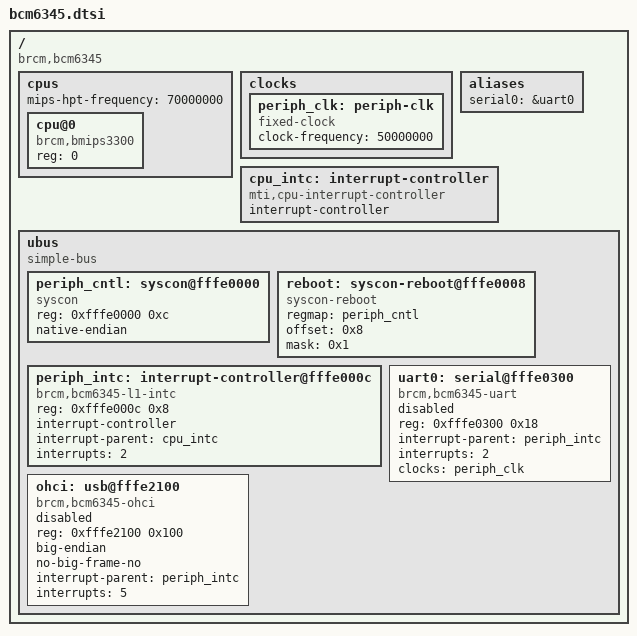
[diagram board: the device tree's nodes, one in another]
/ {
	#address-cells = <1>;
	#size-cells = <1>;
	compatible = "brcm,bcm6345";

	cpus {
		#address-cells = <1>;
		#size-cells = <0>;

		mips-hpt-frequency = <70000000>;

		cpu@0 {
			compatible = "brcm,bmips3300";
			device_type = "cpu";
			reg = <0>;
		};
	};

	clocks {
		periph_clk: periph-clk {
			compatible = "fixed-clock";
			#clock-cells = <0>;
			clock-frequency = <50000000>;
		};
	};

	aliases {
		serial0 = &uart0;
	};

	cpu_intc: interrupt-controller {
		#address-cells = <0>;
		compatible = "mti,cpu-interrupt-controller";

		interrupt-controller;
		#interrupt-cells = <1>;
	};

	ubus {
		#address-cells = <1>;
		#size-cells = <1>;

		compatible = "simple-bus";
		ranges;

		periph_cntl: syscon@fffe0000 {
			compatible = "syscon";
			reg = <0xfffe0000 0xc>;
			native-endian;
		};

		reboot: syscon-reboot@fffe0008 {
			compatible = "syscon-reboot";
			regmap = <&periph_cntl>;
			offset = <0x8>;
			mask = <0x1>;
		};

		periph_intc: interrupt-controller@fffe000c {
			compatible = "brcm,bcm6345-l1-intc";
			reg = <0xfffe000c 0x8>;

			interrupt-controller;
			#interrupt-cells = <1>;

			interrupt-parent = <&cpu_intc>;
			interrupts = <2>;
		};

		uart0: serial@fffe0300 {
			compatible = "brcm,bcm6345-uart";
			reg = <0xfffe0300 0x18>;

			interrupt-parent = <&periph_intc>;
			interrupts = <2>;

			clocks = <&periph_clk>;

			status = "disabled";
		};

		ohci: usb@fffe2100 {
			compatible = "brcm,bcm6345-ohci", "generic-ohci";
			reg = <0xfffe2100 0x100>;
			big-endian;
			no-big-frame-no;

			interrupt-parent = <&periph_intc>;
			interrupts = <5>;

			status = "disabled";
		};
	};
};
